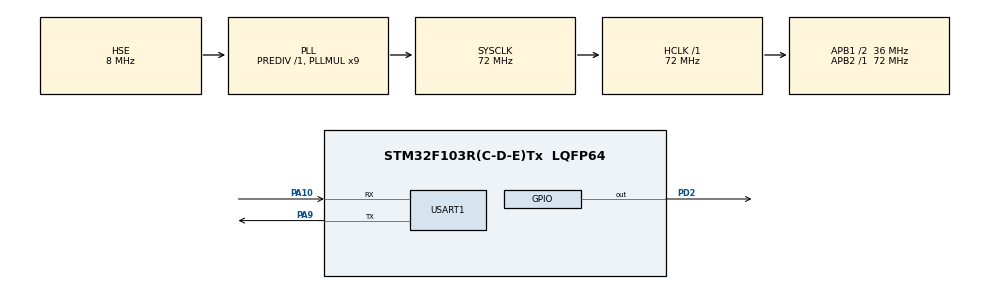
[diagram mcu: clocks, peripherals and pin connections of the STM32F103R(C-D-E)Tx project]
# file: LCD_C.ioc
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Mcu.Family=STM32F1
Mcu.Name=STM32F103R(C-D-E)Tx
Mcu.Package=LQFP64
NVIC.PriorityGroup=NVIC_PRIORITYGROUP_4
PA10.Mode=Asynchronous
PA10.Signal=USART1_RX
PA13.Mode=Serial_Wire
PA13.Signal=SYS_JTMS-SWDIO
PA14.Mode=Serial_Wire
PA14.Signal=SYS_JTCK-SWCLK
PA9.Mode=Asynchronous
PA9.Signal=USART1_TX
PD0-OSC_IN.Mode=HSE-External-Oscillator
PD0-OSC_IN.Signal=RCC_OSC_IN
PD1-OSC_OUT.Mode=HSE-External-Oscillator
PD1-OSC_OUT.Signal=RCC_OSC_OUT
PD2.Signal=GPIO_Output
ProjectManager.HeapSize=0x200
ProjectManager.StackSize=0x400
ProjectManager.TargetToolchain=SW4STM32
RCC.AHBFreq_Value=72000000
RCC.APB1CLKDivider=RCC_HCLK_DIV2
RCC.APB1Freq_Value=36000000
RCC.APB1TimFreq_Value=72000000
RCC.APB2Freq_Value=72000000
RCC.APB2TimFreq_Value=72000000
RCC.HCLKFreq_Value=72000000
RCC.PLLMUL=RCC_PLL_MUL9
RCC.PLLSourceVirtual=RCC_PLLSOURCE_HSE
RCC.SYSCLKFreq_VALUE=72000000
RCC.SYSCLKSource=RCC_SYSCLKSOURCE_PLLCLK
RCC.USBFreq_Value=72000000
USART1.VirtualMode=VM_ASYNC
board=custom

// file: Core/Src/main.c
/* USER CODE BEGIN Header */
/**
  ******************************************************************************
  * @file           : main.c
  * @brief          : Main program body
  ******************************************************************************
  * @attention
  *
  * <h2><center>&copy; Copyright (c) 2023 STMicroelectronics.
  * All rights reserved.</center></h2>
  *
  * This software component is licensed by ST under BSD 3-Clause license,
  * the "License"; You may not use this file except in compliance with the
  * License. You may obtain a copy of the License at:
  *                        opensource.org/licenses/BSD-3-Clause
  *
  ******************************************************************************
  */
/* USER CODE END Header */
#include "main.h"
#include "usart.h"
#include "gpio.h"

/* USER CODE BEGIN Includes */
#include "retarget.h"
#include "lcd.h"
/* USER CODE END Includes */

void SystemClock_Config(void);

int main(void)
{
  /* USER CODE BEGIN 1 */
    uint8_t x = 0;
    uint8_t lcd_id[12];
  /* USER CODE END 1 */

  /* MCU Configuration--------------------------------------------------------*/

  /* Reset of all peripherals, Initializes the Flash interface and the Systick. */
  HAL_Init();

  /* USER CODE BEGIN Init */
    RetargetInit(&huart1);
  /* USER CODE END Init */

  /* Configure the system clock */
  SystemClock_Config();

  /* Initialize all configured peripherals */
  MX_GPIO_Init();
  MX_USART1_UART_Init();
  /* USER CODE BEGIN 2 */
    delay_init(72);
    lcd_init();
//    lcd_show_char(10, 40, 'A', 12, 0, RED);
//    lcd_show_string(10, 40, 240, 32, 32, "STM32", RED);
    g_point_color = RED;
    sprintf((char *)lcd_id, "LCD ID:%04X", lcddev.id);  /* 将LCD ID打印到lcd_id数组 */
    printf("%04X\r\n", lcddev.id);
  /* USER CODE END 2 */

  /* Infinite loop */
  /* USER CODE BEGIN WHILE */
    printf("LCD_C Hello World!\r\n");
  while (1)
  {
      switch (x)
      {
          case 0:
              lcd_clear(WHITE);
              break;

          case 1:
              lcd_clear(BLACK);
              break;

          case 2:
              lcd_clear(BLUE);
              break;

          case 3:
              lcd_clear(RED);
              break;

          case 4:
              lcd_clear(MAGENTA);
              break;

          case 5:
              lcd_clear(GREEN);
              break;

          case 6:
              lcd_clear(CYAN);
              break;

          case 7:
              lcd_clear(YELLOW);
              break;

          case 8:
              lcd_clear(BRRED);
              break;

          case 9:
              lcd_clear(GRAY);
              break;

          case 10:
              lcd_clear(LGRAY);
              break;

          case 11:
              lcd_clear(BROWN);
              break;
      }

      lcd_show_string(10, 40, 240, 32, 32, "STM32", RED);
      lcd_show_string(10, 80, 240, 24, 24, "TFTLCD TEST", RED);
      lcd_show_string(10, 110, 240, 16, 16, "ATOM@ALIENTEK", RED);
      lcd_show_string(10, 130, 240, 16, 16, (char *)lcd_id, RED); /* 显示LCD ID */
      x++;

      if (x == 12)
          x = 0;

      HAL_GPIO_TogglePin(GPIOD, GPIO_PIN_2); /* 红灯闪烁 */
      delay_ms(1000);
    /* USER CODE END WHILE */

  }
}

void SystemClock_Config(void)
{
  RCC_OscInitTypeDef RCC_OscInitStruct = {0};
  RCC_ClkInitTypeDef RCC_ClkInitStruct = {0};

  /** Initializes the RCC Oscillators according to the specified parameters
  * in the RCC_OscInitTypeDef structure.
  */
  RCC_OscInitStruct.OscillatorType = RCC_OSCILLATORTYPE_HSE;
  RCC_OscInitStruct.HSEState = RCC_HSE_ON;
  RCC_OscInitStruct.HSEPredivValue = RCC_HSE_PREDIV_DIV1;
  RCC_OscInitStruct.HSIState = RCC_HSI_ON;
  RCC_OscInitStruct.PLL.PLLState = RCC_PLL_ON;
  RCC_OscInitStruct.PLL.PLLSource = RCC_PLLSOURCE_HSE;
  RCC_OscInitStruct.PLL.PLLMUL = RCC_PLL_MUL9;
  if (HAL_RCC_OscConfig(&RCC_OscInitStruct) != HAL_OK)
  {
    Error_Handler();
  }
  /** Initializes the CPU, AHB and APB buses clocks
  */
  RCC_ClkInitStruct.ClockType = RCC_CLOCKTYPE_HCLK|RCC_CLOCKTYPE_SYSCLK
                              |RCC_CLOCKTYPE_PCLK1|RCC_CLOCKTYPE_PCLK2;
  RCC_ClkInitStruct.SYSCLKSource = RCC_SYSCLKSOURCE_PLLCLK;
  RCC_ClkInitStruct.AHBCLKDivider = RCC_SYSCLK_DIV1;
  RCC_ClkInitStruct.APB1CLKDivider = RCC_HCLK_DIV2;
  RCC_ClkInitStruct.APB2CLKDivider = RCC_HCLK_DIV1;

  if (HAL_RCC_ClockConfig(&RCC_ClkInitStruct, FLASH_LATENCY_2) != HAL_OK)
  {
    Error_Handler();
  }
}

void Error_Handler(void)
{
  __disable_irq();
  while (1)
  {
  }
}

/************************ (C) COPYRIGHT STMicroelectronics *****END OF FILE****/
